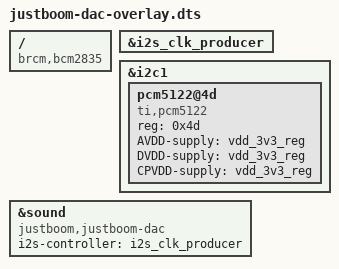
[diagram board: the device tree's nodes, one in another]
// Definitions for JustBoom DAC
/dts-v1/;
/plugin/;

/ {
	compatible = "brcm,bcm2835";

	fragment@0 {
		target = <&i2s_clk_producer>;
		__overlay__ {
			status = "okay";
		};
	};

	fragment@1 {
		target = <&i2c1>;
		__overlay__ {
			#address-cells = <1>;
			#size-cells = <0>;
			status = "okay";

			pcm5122@4d {
				#sound-dai-cells = <0>;
				compatible = "ti,pcm5122";
				reg = <0x4d>;
				AVDD-supply = <&vdd_3v3_reg>;
				DVDD-supply = <&vdd_3v3_reg>;
				CPVDD-supply = <&vdd_3v3_reg>;
				status = "okay";
			};
		};
	};

	fragment@2 {
		target = <&sound>;
		frag2: __overlay__ {
			compatible = "justboom,justboom-dac";
			i2s-controller = <&i2s_clk_producer>;
			status = "okay";
		};
	};

	__overrides__ {
		24db_digital_gain = <&frag2>,"justboom,24db_digital_gain?";
	};
};
